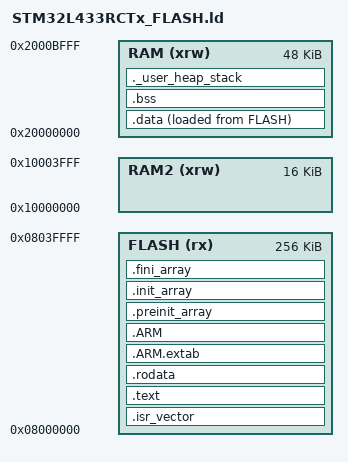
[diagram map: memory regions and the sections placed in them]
/*
*****************************************************************************
**

**  File        : LinkerScript.ld
**
**  Abstract    : Linker script for STM32L433RCTx Device with
**                256KByte FLASH, 48KByte RAM
**
**                Set heap size, stack size and stack location according
**                to application requirements.
**
**                Set memory bank area and size if external memory is used.
**
**  Target      : STMicroelectronics STM32
**
**
**  Distribution: The file is distributed as is, without any warranty
**                of any kind.
**
**  (c)Copyright Ac6.
**  You may use this file as-is or modify it according to the needs of your
**  project. Distribution of this file (unmodified or modified) is not
**  permitted. Ac6 permit registered System Workbench for MCU users the
**  rights to distribute the assembled, compiled & linked contents of this
**  file as part of an application binary file, provided that it is built
**  using the System Workbench for MCU toolchain.
**
*****************************************************************************
*/

/* Entry Point */
ENTRY(Reset_Handler)

/* Highest address of the user mode stack */
/*_estack = 0x2000C000;*/    /* end of RAM */
_estack = ORIGIN(RAM) + LENGTH(RAM);	/* end of "RAM" Ram type memory */
/* Generate a link error if heap and stack don't fit into RAM */
_Min_Heap_Size = 0x200;      /* required amount of heap  */
_Min_Stack_Size = 0x400; /* required amount of stack */

/* Specify the memory areas */
MEMORY
{
RAM (xrw)      : ORIGIN = 0x20000000, LENGTH = 48K
RAM2 (xrw)      : ORIGIN = 0x10000000, LENGTH = 16K
FLASH (rx)      : ORIGIN = 0x8000000, LENGTH = 256K
}

/* Define output sections */
/*ga */
PROVIDE ( _Stack_Limit = _estack - _Min_Stack_Size );
SECTIONS
{
  /* The startup code goes first into FLASH */
  .isr_vector :
  {
    . = ALIGN(8);
    KEEP(*(.isr_vector)) /* Startup code */
    . = ALIGN(8);
  } >FLASH

  /* The program code and other data goes into FLASH */
  .text :
  {
    . = ALIGN(8);
    *(.text)           /* .text sections (code) */
    *(.text*)          /* .text* sections (code) */
    *(.glue_7)         /* glue arm to thumb code */
    *(.glue_7t)        /* glue thumb to arm code */
    *(.vfp11_veneer)   /*ga */
    *(.v4_bx)          /*ga */
    *(.eh_frame)

    KEEP (*(.init))
    KEEP (*(.fini))

    . = ALIGN(8);
    _etext = .;        /* define a global symbols at end of code */
  } >FLASH

  /* Constant data goes into FLASH */
  .rodata :
  {
    . = ALIGN(8);
    *(.rodata)         /* .rodata sections (constants, strings, etc.) */
    *(.rodata*)        /* .rodata* sections (constants, strings, etc.) */
    . = ALIGN(8);
  } >FLASH

  .ARM.extab   :
  {
  . = ALIGN(8);
  *(.ARM.extab* .gnu.linkonce.armextab.*)
  . = ALIGN(8);
  } >FLASH
  .ARM : {
	. = ALIGN(8);
    __exidx_start = .;
    *(.ARM.exidx*)
    __exidx_end = .;
	. = ALIGN(8);
  } >FLASH

  .preinit_array     :
  {
	. = ALIGN(8);
    PROVIDE_HIDDEN (__preinit_array_start = .);
    KEEP (*(.preinit_array*))
    PROVIDE_HIDDEN (__preinit_array_end = .);
	. = ALIGN(8);
  } >FLASH

  .init_array :
  {
	. = ALIGN(8);
    PROVIDE_HIDDEN (__init_array_start = .);
    KEEP (*(SORT(.init_array.*)))
    KEEP (*(.init_array*))
    PROVIDE_HIDDEN (__init_array_end = .);
	. = ALIGN(8);
  } >FLASH
  .fini_array :
  {
	. = ALIGN(8);
    PROVIDE_HIDDEN (__fini_array_start = .);
    KEEP (*(SORT(.fini_array.*)))
    KEEP (*(.fini_array*))
    PROVIDE_HIDDEN (__fini_array_end = .);
	. = ALIGN(8);
  } >FLASH

  /* used by the startup to initialize data */
  _sidata = LOADADDR(.data);

  /* Initialized data sections goes into RAM, load LMA copy after code */
  .data :
  {
    . = ALIGN(8);
    _sdata = .;        /* create a global symbol at data start */
    *(.data)           /* .data sections */
    *(.data*)          /* .data* sections */

    . = ALIGN(8);
    _edata = .;        /* define a global symbol at data end */
  } >RAM AT> FLASH


  /* Uninitialized data section */
  . = ALIGN(4);
  .bss :
  {
    /* This is used by the startup in order to initialize the .bss secion */
    _sbss = .;         /* define a global symbol at bss start */
    __bss_start__ = _sbss;
    *(.bss)
    *(.bss*)
    *(COMMON)

    . = ALIGN(4);
    _ebss = .;         /* define a global symbol at bss end */
    __bss_end__ = _ebss;
  } >RAM

  /* User_heap_stack section, used to check that there is enough RAM left */
  ._user_heap_stack :
  {
    . = ALIGN(8);
    PROVIDE ( end = . );
    PROVIDE ( _end = . );
    PROVIDE ( _exit = . );  /* ga */
    . = . + _Min_Heap_Size;
    /* begining of ga */
    PROVIDE ( _usrstack = . );  /* ga */
    . = ALIGN(8);
    _susrstack = .;
    . = . + _Min_Stack_Size;
    . = ALIGN(8);
    _eusrstack = .;
  } >RAM
    /* end of ga */


  /*beginning of ga */

  PROVIDE (_stackend = ORIGIN(RAM) + LENGTH(RAM) - _Min_Stack_Size);
  /* end of ga */


  /* after that it's only debugging information. */

  /* remove the debugging information from the standard libraries */
/*
  /DISCARD/ :
  {
    libc.a ( * )
    libm.a ( * )
    libgcc.a ( * )
  }

*/

    /* Stabs debugging sections.  */
    .stab          0 : { *(.stab) }
    .stabstr       0 : { *(.stabstr) }
    .stab.excl     0 : { *(.stab.excl) }
    .stab.exclstr  0 : { *(.stab.exclstr) }
    .stab.index    0 : { *(.stab.index) }
    .stab.indexstr 0 : { *(.stab.indexstr) }
    .comment       0 : { *(.comment) }
    /* DWARF debug sections.
       Symbols in the DWARF debugging sections are relative to the beginning
       of the section so we begin them at 0.  */
    /* DWARF 1 */
    .debug          0 : { *(.debug) }
    .line           0 : { *(.line) }
    /* GNU DWARF 1 extensions */
    .debug_srcinfo  0 : { *(.debug_srcinfo) }
    .debug_sfnames  0 : { *(.debug_sfnames) }
    /* DWARF 1.1 and DWARF 2 */
    .debug_aranges  0 : { *(.debug_aranges) }
    .debug_pubnames 0 : { *(.debug_pubnames) }
    /* DWARF 2 */
    .debug_info     0 : { *(.debug_info .gnu.linkonce.wi.*) }
    .debug_abbrev   0 : { *(.debug_abbrev) }
    .debug_line     0 : { *(.debug_line) }
    .debug_frame    0 : { *(.debug_frame) }
    .debug_str      0 : { *(.debug_str) }
    .debug_loc      0 : { *(.debug_loc) }
    .debug_macinfo  0 : { *(.debug_macinfo) }
    /* SGI/MIPS DWARF 2 extensions */
    .debug_weaknames 0 : { *(.debug_weaknames) }
    .debug_funcnames 0 : { *(.debug_funcnames) }
    .debug_typenames 0 : { *(.debug_typenames) }
    .debug_varnames  0 : { *(.debug_varnames) }


  .ARM.attributes 0 : { *(.ARM.attributes) }
}
